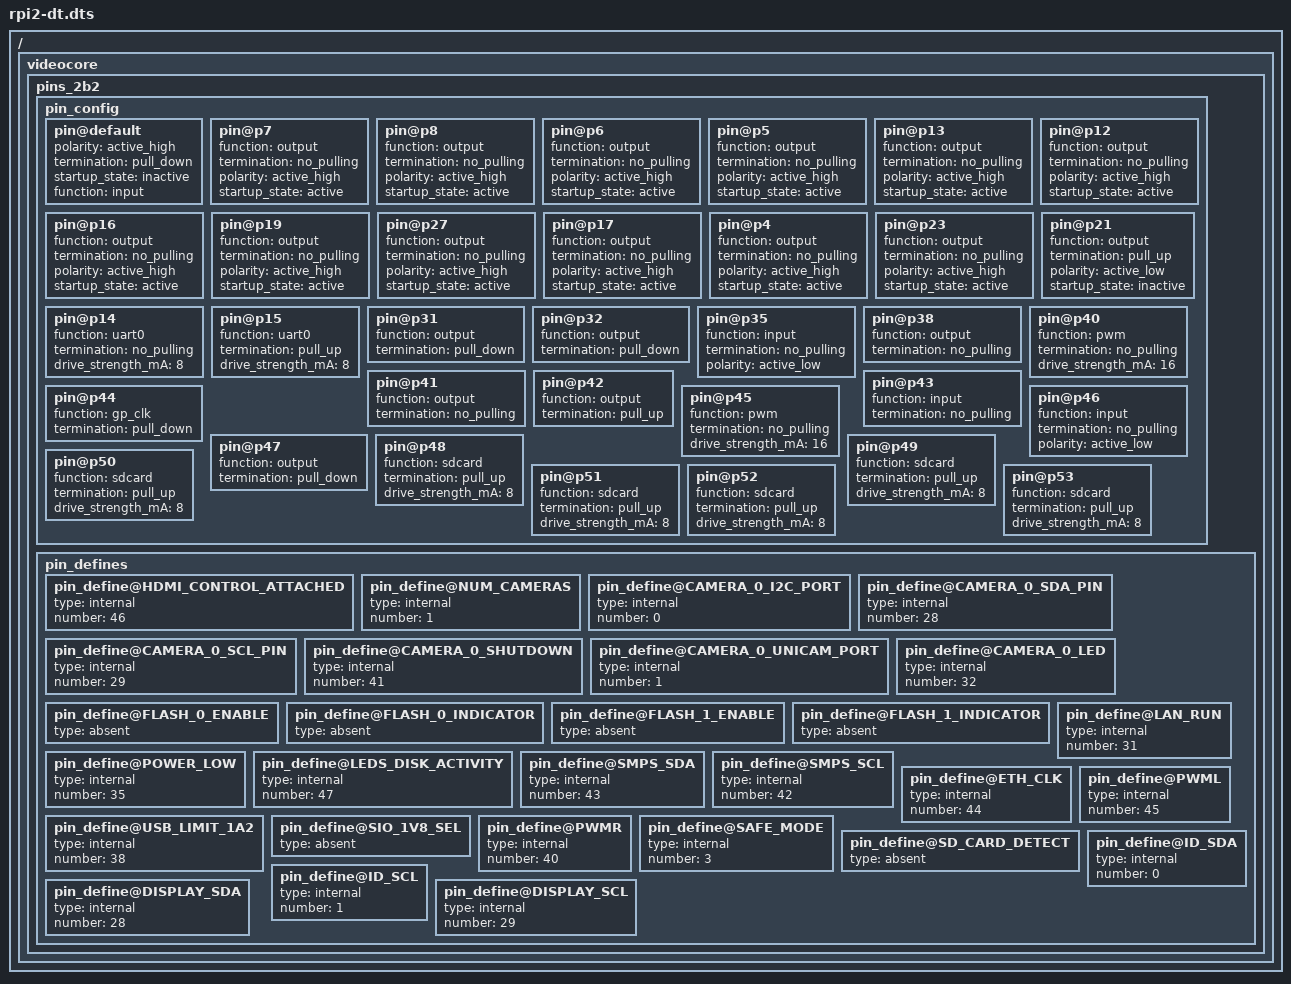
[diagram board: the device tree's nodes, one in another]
/dts-v1/;

/ {
   videocore {
      pins_2b2 { // Pi 2 Model B rev 1.1
         pin_config {
            pin@default {
               polarity = "active_high";
               termination = "pull_down";
               startup_state = "inactive";
               function = "input";
            }; // pin

            // Power to bulgin connectors on serial ports 0-7
            pin@p7 { function = "output";  termination = "no_pulling"; polarity="active_high"; startup_state="active"; };
            pin@p8 { function = "output";  termination = "no_pulling"; polarity="active_high"; startup_state="active"; };
            pin@p6 { function = "output";  termination = "no_pulling"; polarity="active_high"; startup_state="active"; };
            pin@p5 { function = "output";  termination = "no_pulling"; polarity="active_high"; startup_state="active"; };
            pin@p13 { function = "output";  termination = "no_pulling"; polarity="active_high"; startup_state="active"; };
            pin@p12 { function = "output";  termination = "no_pulling"; polarity="active_high"; startup_state="active"; };
            pin@p16 { function = "output";  termination = "no_pulling"; polarity="active_high"; startup_state="active"; };
            pin@p19 { function = "output";  termination = "no_pulling"; polarity="active_high"; startup_state="active"; };

            // External AUX power
            pin@p27 { function = "output";  termination = "no_pulling"; polarity="active_high"; startup_state="active"; };
            // Internal bank1 +12 VDC 
            pin@p17 { function = "output";  termination = "no_pulling"; polarity="active_high"; startup_state="active"; };
            // Internal bank1 +12 VDC 
            pin@p4 { function = "output";  termination = "no_pulling"; polarity="active_high"; startup_state="active"; };
            // Internal DC-DC
            pin@p23 { function = "output";  termination = "no_pulling"; polarity="active_high"; startup_state="active"; };

            // Roving Networks blue-tooth radio on console, reset, active-low: i.e. if low, radio is off
            pin@p21 { function = "output";  termination = "pull_up"; polarity="active_low"; startup_state="inactive"; };

            pin@p14 { function = "uart0";  termination = "no_pulling"; drive_strength_mA = < 8 >; }; // TX uart0
            pin@p15 { function = "uart0";  termination = "pull_up"; drive_strength_mA = < 8 >; }; // RX uart0
            // The firmware changes I2C pin functions on the fly, returning them to inputs when done. But pins 28&29 are
            // not used on a 1.1 Pi2, so the I2C0 function ends up multiply mapped (bad). therefore don't statically map.
            // pin@p28 { function = "i2c0";   termination = "pull_up";    }; // I2C 0 SDA
            // pin@p29 { function = "i2c0";   termination = "pull_up";    }; // I2C 0 SCL
            pin@p31 { function = "output"; termination = "pull_down"; }; // LAN_RUN
            pin@p32 { function = "output"; termination = "pull_down"; }; // Camera LED
            pin@p35 { function = "input";  termination = "no_pulling"; polarity = "active_low"; }; // Power low
            pin@p38 { function = "output"; termination = "no_pulling";    }; // USB current limit (0=600mA, 1=1200mA)
            pin@p40 { function = "pwm";    termination = "no_pulling"; drive_strength_mA = < 16 >; }; // Right audio
            pin@p41 { function = "output"; termination = "no_pulling";    }; // Camera shutdown
            // Communicate with the SMPS by "bit-bashing" the I2C protocol on GPIOs 42 and 43
            pin@p42 { function = "output"; termination = "pull_up";    }; // SMPS_SCL
            pin@p43 { function = "input";  termination = "no_pulling";    }; // SMPS_SDA
            pin@p44 { function = "gp_clk"; termination = "pull_down"; }; // ETH_CLK - Ethernet 25MHz output
            pin@p45 { function = "pwm";    termination = "no_pulling"; drive_strength_mA = < 16 >; }; // Left audio
            pin@p46 { function = "input";  termination = "no_pulling"; polarity = "active_low"; }; // Hotplug
            pin@p47 { function = "output"; termination = "pull_down"; }; // activity LED
            pin@p48 { function = "sdcard"; termination = "pull_up";    drive_strength_mA = < 8 >; }; // SD CLK
            pin@p49 { function = "sdcard"; termination = "pull_up";    drive_strength_mA = < 8 >; }; // SD CMD
            pin@p50 { function = "sdcard"; termination = "pull_up";    drive_strength_mA = < 8 >; }; // SD D0
            pin@p51 { function = "sdcard"; termination = "pull_up";    drive_strength_mA = < 8 >; }; // SD D1
            pin@p52 { function = "sdcard"; termination = "pull_up";    drive_strength_mA = < 8 >; }; // SD D2
            pin@p53 { function = "sdcard"; termination = "pull_up";    drive_strength_mA = < 8 >; }; // SD D3
         }; // pin_config

         pin_defines {
            pin_define@HDMI_CONTROL_ATTACHED {
               type = "internal";
               number = <46>;
            };
            pin_define@NUM_CAMERAS {
               type = "internal";
               number = <1>;
            };
            pin_define@CAMERA_0_I2C_PORT {
               type = "internal";
               number = <0>;
            };
            pin_define@CAMERA_0_SDA_PIN {
               type = "internal";
               number = <28>;
            };
            pin_define@CAMERA_0_SCL_PIN {
               type = "internal";
               number = <29>;
            };
            pin_define@CAMERA_0_SHUTDOWN {
               type = "internal";
               number = <41>;
            };
            pin_define@CAMERA_0_UNICAM_PORT {
               type = "internal";
               number = <1>;
            };
            pin_define@CAMERA_0_LED {
               type = "internal";
               number = <32>;
            };
            pin_define@FLASH_0_ENABLE {
               type = "absent";
            };
            pin_define@FLASH_0_INDICATOR {
               type = "absent";
            };
            pin_define@FLASH_1_ENABLE {
               type = "absent";
            };
            pin_define@FLASH_1_INDICATOR {
               type = "absent";
            };
            pin_define@POWER_LOW {
               type = "internal";
               number = <35>;
            };
            pin_define@LEDS_DISK_ACTIVITY {
               type = "internal";
               number = <47>;
            };
            pin_define@LAN_RUN {
               type = "internal";
               number = <31>;
            };
            pin_define@SMPS_SDA {
               type = "internal";
               number = <43>;
            };
            pin_define@SMPS_SCL {
               type = "internal";
               number = <42>;
            };
            pin_define@ETH_CLK {
               type = "internal";
               number = <44>;
            };
            pin_define@USB_LIMIT_1A2 {
               type = "internal";
               number = <38>;
            };
            pin_define@SIO_1V8_SEL {
               type = "absent";
            };
            pin_define@PWML {
               type = "internal";
               number = <45>;
            };
            pin_define@PWMR {
               type = "internal";
               number = <40>;
            };
            pin_define@SAFE_MODE {
               type = "internal";
               number = <3>;
            };
            pin_define@SD_CARD_DETECT {
               type = "absent";
            };
            pin_define@ID_SDA {
               type = "internal";
               number = <0>;
            };
            pin_define@ID_SCL {
               type = "internal";
               number = <1>;
            };
            pin_define@DISPLAY_SDA {
               type = "internal";
               number = <28>;
            };
            pin_define@DISPLAY_SCL {
               type = "internal";
               number = <29>;
            };
         }; // pin_defines
      }; // pins
   };
};
